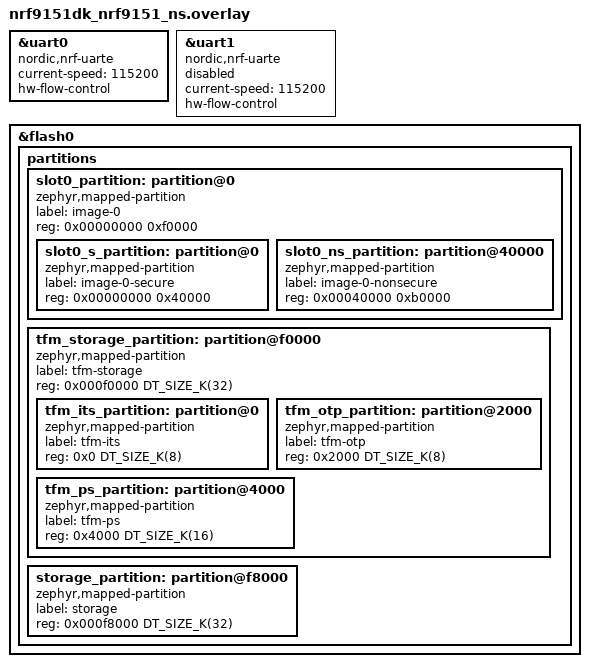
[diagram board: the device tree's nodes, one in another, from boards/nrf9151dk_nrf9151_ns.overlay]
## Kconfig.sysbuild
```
#
# Copyright (c) 2026 Nordic Semiconductor
#
# SPDX-License-Identifier: LicenseRef-Nordic-5-Clause
#

config PARTITION_MANAGER
	default n if !SOC_SERIES_NRF91

source "share/sysbuild/Kconfig"
```

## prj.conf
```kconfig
#
# Copyright (c) 2021-2023 Nordic Semiconductor ASA
#
# SPDX-License-Identifier: LicenseRef-Nordic-5-Clause
#

CONFIG_ZTEST=y
```

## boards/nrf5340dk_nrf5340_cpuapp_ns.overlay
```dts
/*
 * Copyright (c) 2026 Nordic Semiconductor ASA
 *
 * SPDX-License-Identifier: LicenseRef-Nordic-5-Clause
 */

/delete-node/ &boot_partition;
/delete-node/ &slot0_partition;
/delete-node/ &slot1_partition;
/delete-node/ &tfm_ps_partition;
/delete-node/ &tfm_its_partition;
/delete-node/ &tfm_otp_partition;
/delete-node/ &storage_partition;

&flash0 {
	partitions {
		slot0_s_partition: partition@0 {
			compatible = "zephyr,mapped-partition";
			label = "image-0-secure";
			reg = <0x0 0x40000>;
		};

		slot0_ns_partition: partition@40000 {
			compatible = "zephyr,mapped-partition";
			label = "image-0-nonsecure";
			reg = <0x40000 0xb4000>;
		};

		tfm_storage_partition: partition@f4000 {
			compatible = "zephyr,mapped-partition";
			label = "tfm-storage";
			reg = <0xf4000 DT_SIZE_K(48)>;
			ranges = <0x0 0xf4000 DT_SIZE_K(48)>;
			#address-cells = <1>;
			#size-cells = <1>;

			tfm_its_partition: partition@0 {
				compatible = "zephyr,mapped-partition";
				label = "tfm-its";
				reg = <0x0 DT_SIZE_K(8)>;
			};

			tfm_otp_partition: partition@4000 {
				compatible = "zephyr,mapped-partition";
				label = "tfm-otp";
				reg = <0x4000 DT_SIZE_K(8)>;
			};

			tfm_ps_partition: partition@8000 {
				compatible = "zephyr,mapped-partition";
				label = "tfm-ps";
				reg = <0x8000 DT_SIZE_K(16)>;
			};
		};
	};
};

/ {
	/delete-node/ nordic-tz-secure;
	/delete-node/ nordic-tz-nonsecure;

	nordic-tz-secure {
		compatible = "nordic,tz-secure";
		code-partitions = <&slot0_s_partition>;
		data-partitions = <&tfm_ps_partition>,
				  <&tfm_its_partition>,
				  <&tfm_otp_partition>;
	};

	nordic-tz-nonsecure {
		compatible = "nordic,tz-nonsecure";
		code-partitions = <&slot0_ns_partition>;
	};
};
```

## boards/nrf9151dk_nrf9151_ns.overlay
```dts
/*
 * Copyright (c) 2026 Nordic Semiconductor ASA
 *
 * SPDX-License-Identifier: LicenseRef-Nordic-5-Clause
 */

&uart0 {
	compatible = "nordic,nrf-uarte";
	current-speed = <115200>;
	status = "okay";
	hw-flow-control;
};

&uart1 {
	compatible = "nordic,nrf-uarte";
	current-speed = <115200>;
	/* Set to disabled in application, since TF-M will be using it. */
	status = "disabled";
	hw-flow-control;
};

/* Custom partition table providing TF-M secure / non-secure images and the
 * PS / ITS / OTP storage area used by TF-M. No bootloader (NSIB / MCUboot)
 * is placed in front, matching what Partition Manager used to produce for
 * this test.
 */
/delete-node/ &boot_partition;
/delete-node/ &slot0_partition;
/delete-node/ &slot1_partition;
/delete-node/ &tfm_ps_partition;
/delete-node/ &tfm_its_partition;
/delete-node/ &tfm_otp_partition;
/delete-node/ &storage_partition;

&flash0 {
	/*
	 * 0x0000_0000  Primary image area           (960 kB)
	 *   0x0000_0000  Primary secure image       (256 kB)
	 *   0x0004_0000  Primary non-secure image   (704 kB)
	 * 0x000f_0000  TF-M storage area            ( 32 kB)
	 *   0x000f_0000  TF-M Internal Trusted Stg  (  8 kB)
	 *   0x000f_2000  TF-M OTP / NV counters     (  8 kB)
	 *   0x000f_4000  TF-M Protected Storage     ( 16 kB)
	 * 0x000f_8000  Settings storage             ( 32 kB)
	 */
	partitions {
		ranges;
		#address-cells = <1>;
		#size-cells = <1>;

		slot0_partition: partition@0 {
			compatible = "zephyr,mapped-partition";
			label = "image-0";
			reg = <0x00000000 0xf0000>;
			ranges = <0x0 0x00000000 0xf0000>;
			#address-cells = <1>;
			#size-cells = <1>;

			slot0_s_partition: partition@0 {
				compatible = "zephyr,mapped-partition";
				label = "image-0-secure";
				reg = <0x00000000 0x40000>;
			};

			slot0_ns_partition: partition@40000 {
				compatible = "zephyr,mapped-partition";
				label = "image-0-nonsecure";
				reg = <0x00040000 0xb0000>;
			};
		};

		tfm_storage_partition: partition@f0000 {
			compatible = "zephyr,mapped-partition";
			label = "tfm-storage";
			reg = <0x000f0000 DT_SIZE_K(32)>;
			ranges = <0x0 0x000f0000 DT_SIZE_K(32)>;
			#address-cells = <1>;
			#size-cells = <1>;

			tfm_its_partition: partition@0 {
				compatible = "zephyr,mapped-partition";
				label = "tfm-its";
				reg = <0x0 DT_SIZE_K(8)>;
			};

			tfm_otp_partition: partition@2000 {
				compatible = "zephyr,mapped-partition";
				label = "tfm-otp";
				reg = <0x2000 DT_SIZE_K(8)>;
			};

			tfm_ps_partition: partition@4000 {
				compatible = "zephyr,mapped-partition";
				label = "tfm-ps";
				reg = <0x4000 DT_SIZE_K(16)>;
			};
		};

		storage_partition: partition@f8000 {
			compatible = "zephyr,mapped-partition";
			label = "storage";
			reg = <0x000f8000 DT_SIZE_K(32)>;
		};
	};
};

/* SRAM split matching the non-minimal TF-M profile (88 kB secure). */
#include <samples/cellular/nrf91_sram_crypto_partitions.dtsi>
```

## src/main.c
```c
/*
 * Copyright (c) 2021 Nordic Semiconductor ASA
 *
 * SPDX-License-Identifier: LicenseRef-Nordic-5-Clause
 */

#include <zephyr/ztest.h>
#include <zephyr/devicetree.h>
#include <tfm_ns_interface.h>
#include <tfm_ioctl_api.h>

#include <hal/nrf_gpio.h>

#define TEST_SRAM_BASE       DT_REG_ADDR(DT_NODELABEL(sram0))
#define TEST_SRAM_NS_ADDRESS DT_REG_ADDR(DT_NODELABEL(sram0_ns))
#define TEST_SRAM_S_ADDRESS  DT_REG_ADDR(DT_NODELABEL(sram0_s))
#define TEST_NS_FLASH_ADDR   DT_REG_ADDR(DT_NODELABEL(slot0_ns_partition))

ZTEST_SUITE(test_secure_service, NULL, NULL, NULL, NULL, NULL);

static bool is_secure(intptr_t ptr)
{
	/* We can not use 'arm_cmse_addr_is_secure here since this firmware
	 * is built as non secure.
	 */
	if (ptr >= TEST_SRAM_BASE) {
		/* Check if RAM address is secure */
		return ptr < TEST_SRAM_NS_ADDRESS;
	}

	/* Check if flash address is secure */
	return ptr < TEST_NS_FLASH_ADDR;
}

ZTEST(test_secure_service, test_tfm_read_service)
{
	const uint32_t ficr_info_start = NRF_FICR_S_BASE + offsetof(NRF_FICR_Type, INFO);
	const uint32_t ficr_info_end   = ficr_info_start + sizeof(FICR_INFO_Type);

	uint8_t output[4];
	uint8_t data_length = sizeof(output);
	void *secure_ptr = (size_t *)TEST_SRAM_S_ADDRESS;

	uint32_t err = 0;
	enum tfm_platform_err_t plt_err;

	/* Verify that test objects is stored in non-secure addresses. */
	zassert_true(!is_secure((intptr_t)output),
			 "Test object is not non-secure");

	/* Verify that secure test objects is stored in secure addresses. */
	zassert_true(is_secure((intptr_t)secure_ptr),
						"Test object is not secure");

	/* Verify that the function fails if it is passed secure pointers */
	plt_err = tfm_platform_mem_read(secure_ptr, ficr_info_start, data_length, &err);
	zassert_equal(plt_err, TFM_PLATFORM_ERR_INVALID_PARAM,
						"Did not fail for secure pointer");
	zassert_equal(err, -1, "Did not fail for secure pointer");

	/* Verify that edge addresses in FICR INFO will return expected values */
	/* Normal execution */
	plt_err = tfm_platform_mem_read(output, ficr_info_start, data_length, &err);
	zassert_equal(plt_err, TFM_PLATFORM_ERR_SUCCESS, "Valid address returned an error!");
	zassert_equal(err, 0, "Valid address returned an error!");

	plt_err = tfm_platform_mem_read(output, ficr_info_end - data_length, data_length, &err);
	zassert_equal(plt_err, TFM_PLATFORM_ERR_SUCCESS, "Valid address returned an error!");
	zassert_equal(err, 0, "Valid address returned an error!");

	/* Expect invalid addresses to finish with result -1 */
	plt_err = tfm_platform_mem_read(output, ficr_info_start - 1, data_length, &err);
	zassert_equal(plt_err, TFM_PLATFORM_ERR_INVALID_PARAM,
							"Invalid address returned an unexpected error");
	zassert_equal(err, -1, "Invalid address did not return expected address");

	plt_err = tfm_platform_mem_read(output, ficr_info_end - data_length + 1, data_length, &err);
	zassert_equal(plt_err, TFM_PLATFORM_ERR_INVALID_PARAM,
							"Invalid address returned an unexpected error");
	zassert_equal(err, -1, "Invalid address did not return expected address");

#if defined(FICR_NFC_TAGHEADER0_MFGID_Msk)
	const uint32_t ficr_nfc_start  = NRF_FICR_S_BASE + offsetof(NRF_FICR_Type, NFC);
	const uint32_t ficr_nfc_end    = ficr_nfc_start + sizeof(FICR_NFC_Type);

	/* Verify that edge addresses in FICR NFC will return expected values */
	/* Normal execution */
	plt_err = tfm_platform_mem_read(output, ficr_nfc_start, data_length, &err);
	zassert_equal(plt_err, TFM_PLATFORM_ERR_SUCCESS, "Valid address returned an error!");
	zassert_equal(err, 0, "Valid address returned an error!");

	plt_err = tfm_platform_mem_read(output, ficr_nfc_end - data_length, data_length, &err);
	zassert_equal(plt_err, TFM_PLATFORM_ERR_SUCCESS, "Valid address returned an error!");
	zassert_equal(err, 0, "Valid address returned an error!");

	/* Expect invalid addresses to finish with result -1 */
	plt_err = tfm_platform_mem_read(output, ficr_nfc_start - 1, data_length, &err);
	zassert_equal(plt_err, TFM_PLATFORM_ERR_INVALID_PARAM,
							"Invalid address returned an unexpected error");
	zassert_equal(err, -1, "Invalid address did not return expected address");

	plt_err = tfm_platform_mem_read(output, ficr_nfc_end - data_length + 1, data_length, &err);
	zassert_equal(plt_err, TFM_PLATFORM_ERR_INVALID_PARAM,
							"Invalid address returned an unexpected error");
	zassert_equal(err, -1, "Invalid address did not return expected address");
#endif /* defined(FICR_NFC_TAGHEADER0_MFGID_Msk) */
}

ZTEST(test_secure_service, test_tfm_gpio_service)
{
	uint32_t err = UINT32_MAX;
	enum tfm_platform_err_t plt_err;

#if NRF_GPIO_HAS_SEL
	plt_err = tfm_platform_gpio_pin_mcu_select(0, NRF_GPIO_PIN_SEL_PERIPHERAL, &err);
	zassert_equal(plt_err, TFM_PLATFORM_ERR_SUCCESS,
		      "Valid GPIO mcu select operation returned an unexpected error");
	zassert_equal(err, 0, "Valid GPIO select arguments returned an unexpected result");

	plt_err = tfm_platform_gpio_pin_mcu_select(0, 2, &err);
	zassert_equal(plt_err, TFM_PLATFORM_ERR_SUCCESS,
		      "Valid GPIO mcu select operation returned an unexpected error");
	zassert_equal(err, -1,
		      "Invalid GPIO select mcu argument returned an unexpected result");

	plt_err = tfm_platform_gpio_pin_mcu_select(66, NRF_GPIO_PIN_SEL_NETWORK, &err);
	zassert_equal(plt_err, TFM_PLATFORM_ERR_SUCCESS,
		      "Valid GPIO mcu select operation returned an unexpected error");
	zassert_equal(err, -1,
		      "Invalid GPIO select pin_number argument returned an unexpected result");
#else
	plt_err = tfm_platform_gpio_pin_mcu_select(0, 0x0 /* APPLICATION */, &err);
	zassert_equal(plt_err, TFM_PLATFORM_ERR_NOT_SUPPORTED,
		      "Not supported GPIO mcu select operation returned an unexpected error");
#endif
}
```
